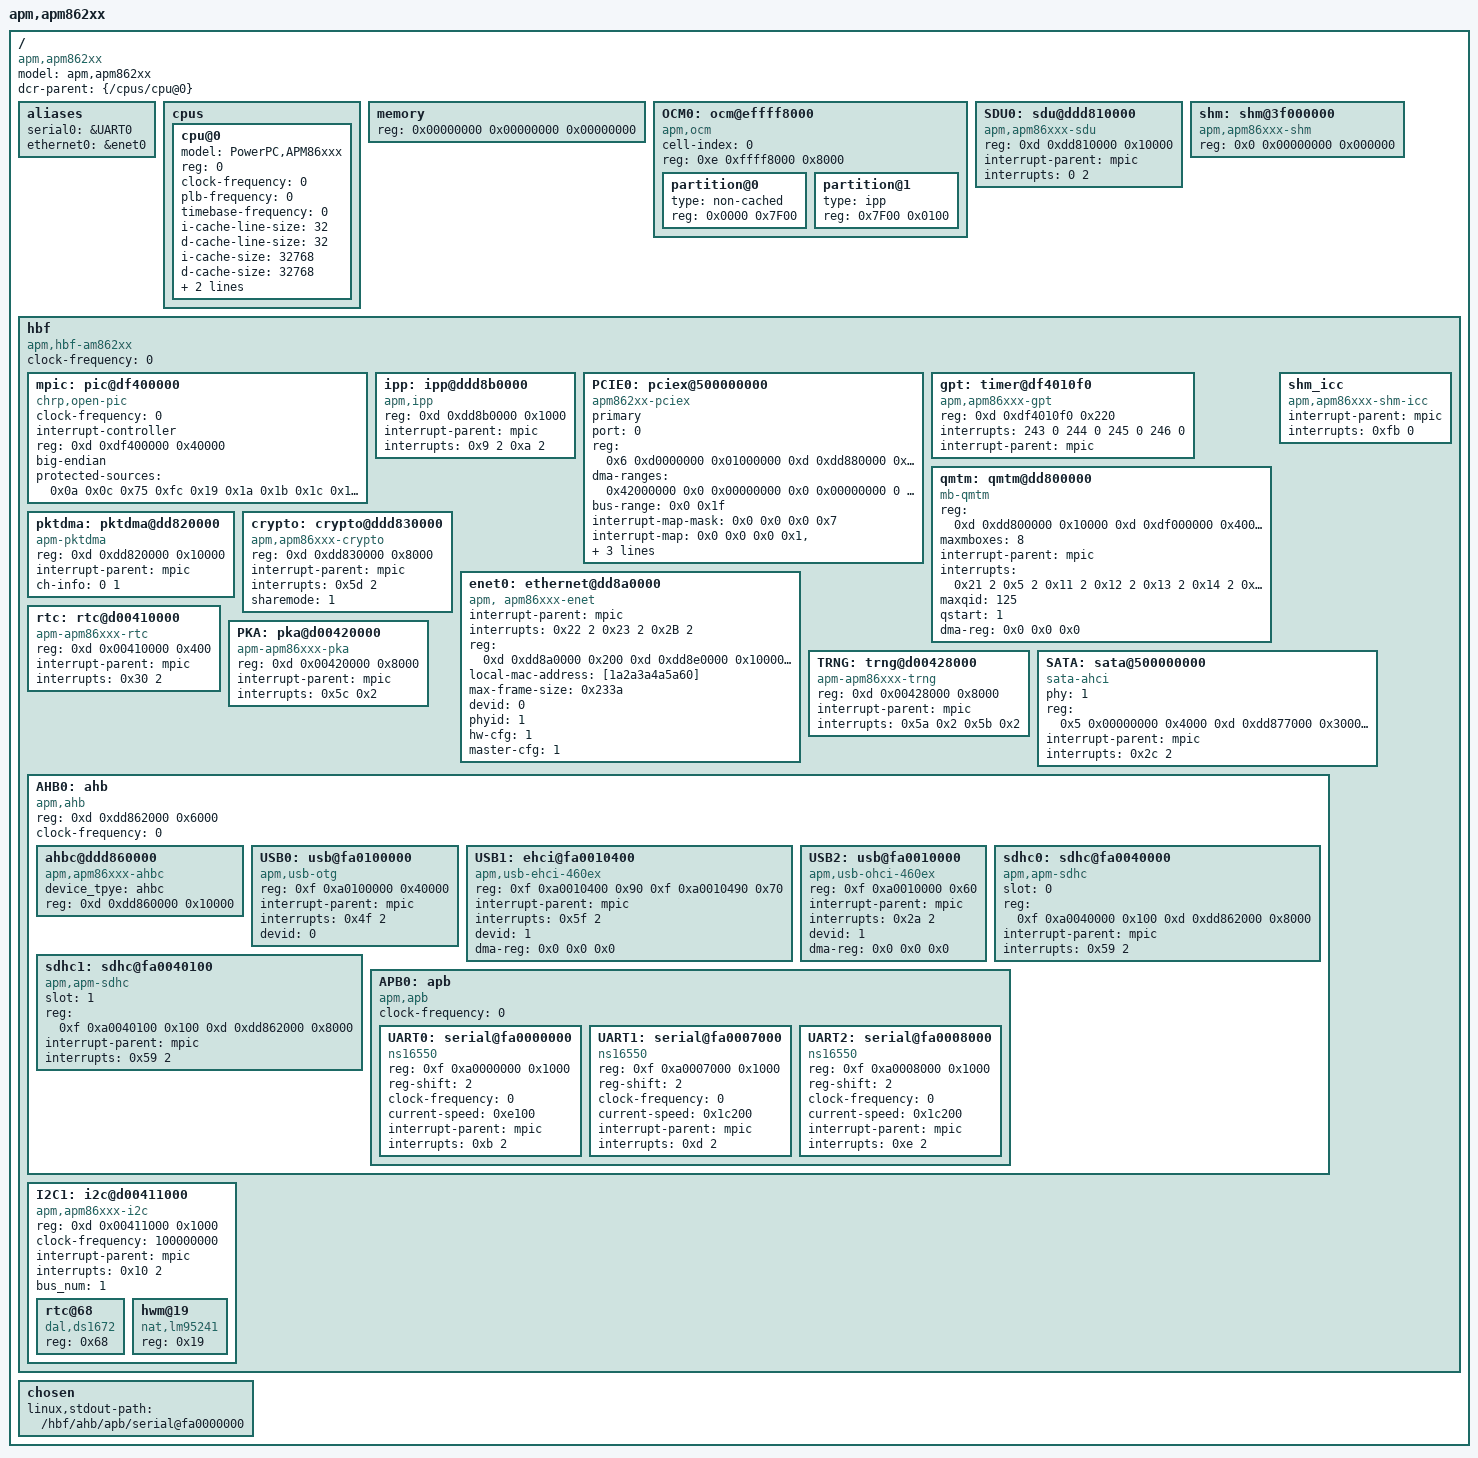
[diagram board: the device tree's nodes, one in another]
/*
 * CPU0 Device Tree Source for APM Serengeti (AM86xxx) Eval Board 
 *
 * Copyright (c) 2010 Applied Micro Circuits Corporation.
 * All rights reserved. Feng Kan <fkan@apm.com>.
 *
 * This file is licensed under the terms of the GNU General Public
 * License version 2.  This program is licensed "as is" without
 * any warranty of any kind, whether express or implied.
 */

/dts-v1/;

/ {
	#address-cells = <2>;
	#size-cells = <1>;
	model = "apm,apm862xx";
	compatible = "apm,apm862xx";
	dcr-parent = <&{/cpus/cpu@0}>;

	aliases {
		serial0 = &UART0;
		ethernet0 = &enet0;
		/*ethernet1 = &enet1;*/
	};

	cpus {
		#address-cells = <1>;
		#size-cells = <0>;

		cpu@0 {
			device_type = "cpu";
			model = "PowerPC,APM86xxx";
			reg = <0>;
			clock-frequency = <0>; /* Filled in by U-Boot */
			plb-frequency = <0>; /* Filled in by U-Boot */
			timebase-frequency = <0>; /* Filled in by U-Boot */
			i-cache-line-size = <32>;
			d-cache-line-size = <32>;
			i-cache-size = <32768>;
			d-cache-size = <32768>;
			dcr-controller;
			dcr-access-method = "native";

			#address-cells = <1>;
			#size-cells = <0>;
		};
	};

	memory {
		device_type = "memory";
		reg = <0x00000000 0x00000000 0x00000000>; /* Filled in by U-Boot */
	};

	OCM0: ocm@effff8000 {
		compatible = "apm,ocm";
		cell-index = <0>;
		reg = <0xe 0xffff8000 0x8000>;
		#size-cells = <1>;
		#address-cells = <1>;
		partition@0 {
			type = "non-cached";
			reg = <0x0000 0x7F00>;
		};
		partition@1 {
			type = "ipp";
			reg = <0x7F00 0x0100>;
		};
	};

	SDU0: sdu@ddd810000 {
		compatible = "apm,apm86xxx-sdu";
		reg = <0xd 0xdd810000 0x10000>;
		interrupt-parent = <&mpic>;
		interrupts = <0 2>;
	};	

	shm: shm@3f000000{
	        compatible = "apm,apm86xxx-shm";
	        reg = <0x0 0x00000000 0x000000>; /* Fill in by U-Boot */
	};

	hbf {
		compatible = "apm,hbf-am862xx", "apm,hbf";
		#address-cells = <2>;
		#size-cells = <1>;
		ranges;
		clock-frequency = <0>; /* Filled in by U-Boot */

                mpic: pic@df400000 {
                        clock-frequency = <0>;
                        interrupt-controller;
                        reg = <0xd 0xdf400000 0x40000>;
			#address-cells = <0>;
                        #interrupt-cells = <2>;
                        compatible = "chrp,open-pic";
                        device_type = "open-pic";
                        big-endian;
			protected-sources = <
                       	0x0a		/* iPP Core1 for other OS */
                       	0x0c		/* UART1 for other OS */
                       	0x75		/* ICC */
			0xfc		/* IPI for other oS */
			0x19 0x1a 0x1b 0x1c 0x1d 0x1e 0x1f 0x20 /* QM mailboxes for core 1*/
			0x26 0x27 0x28 0x29 /* PCIE2 for core 1 */
			0x2e 0x2f	/* USB2 EHCI/OHCI for core 1 */
			0x37 0x38 0x39 0x3a /* PCIE1 for core 1 */
			0xf7 0xf8 0xf9 0xfa /* Timer */
                       	>;
                };

		ipp: ipp@ddd8b0000 {
			compatible = "apm,ipp";
			reg = <0xd 0xdd8b0000 0x1000>;
			interrupt-parent = <&mpic>; 
			interrupts = <  /*iPP Core0 */ 0x9 2  
					/*iPP Core1 */ 0xa 2 >;
		};

		PCIE0: pciex@500000000 {
			device_type = "pci";
			compatible = "apm862xx-pciex", "apm,apm-pciex";
			#interrupt-cells = <1>;
			#size-cells = <2>;
			#address-cells = <3>;
			primary;
			port = <0>;
			status = "ok";
			reg = < 0x6 0xd0000000 0x01000000
				0xd 0xdd880000 0x00008000>;

			ranges = <0x02000000 0x0 0x00000000 0x6 0x00000000 0x0 0x10000000
				  0x02000000 0x0 0x80000000 0x6 0x80000000 0x0 0x10000000
				  0x01000000 0x0 0x10000000 0x6 0x10000000 0x0 0x00010000>;


			dma-ranges = <0x42000000 0x0 0x00000000 0x0 0x00000000 0 0x80000000>;

			bus-range = <0x0 0x1f>;

			interrupt-map-mask = <0x0 0x0 0x0 0x7>;
			interrupt-map = <
				0x0 0x0 0x0 0x1 &mpic 0x33 0x2 
				0x0 0x0 0x0 0x2 &mpic 0x34 0x2 
				0x0 0x0 0x0 0x3 &mpic 0x35 0x2 
				0x0 0x0 0x0 0x4 &mpic 0x36 0x2 >;
		};
/*
		vnet0 {
			device_type = "network";
			compatible = "apm,apm86xxx-vnet";
			local-mac-address = [2a3a4a5a6a60];
			devid = <0>;
			interrupt-parent = <&mpic>;
			interrupts = <0x74 0x2>;
			remote-core-id = <0x01>;
			remote-qm-id = <0x01>;
			remote-msg-idx = <0x01>;
		};
*/
		gpt: timer@df4010f0 {
			compatible = "apm,apm86xxx-gpt";
			reg = <0xd 0xdf4010f0 0x220>;
			interrupts = <243 0 244 0 245 0 246 0>;
			interrupt-parent = <&mpic>;
		};

                qmtm: qmtm@dd800000 {
                        device_type = "qmtm";
                        compatible = "mb-qmtm", "apm,mb-qmtm";
                        #interrupt-cells = <2>;
                        reg =  <0xd 0xdd800000 0x10000   /* QM CSR */
                                0xd 0xdf000000 0x400000  /* QM Fabric */
                                0x3 0xffffd000 0x3fff	/* OCM mailbox */
		 		0xd 0x00000000 0x400000  /* QM lite Fabric */
				0xd 0xdd8d0000 0x10000	/* QM lite CSR */
				0xd 0xdd8b1000 0x240>;	/* iPP QM lite CSR */
			maxmboxes = <8>;
                        interrupt-parent = <&mpic>;
                        interrupts = <  0x21 2  0x5 2 0x11 2 0x12 2 0x13 2 0x14 2 0x15 2 0x16 2 0x17 2 0x18 2>;
			maxqid = <125>;
			qstart = <1>;
			dma-reg = <0x0 0x0 0x0>;			 
                };                
/*
		SLIMPROOFFLOAD { 
			compatible = "apm,slimpro-offload";
			queue = <0 2>;
		}; 
*/
/*
		SRAM0: sram@0x020000000 {
			compatible = "mtd-ram";
			reg = <0x0 0x20000000 0x2000000>; 
			bank-width = <2>;
			#size-cells = <1>;
			#address-cells = <1>;
			partition@0 {
				label = "MTD-RAM Root FS 0";
				reg = <0x00000000 0x01000000>;
			};
			partition@1 {
				label = "MTD-RAM Root FS 1";
				reg = <0x01000000 0x01000000>;
			};
		};
*/
		pktdma: pktdma@dd820000 {
			device_type = "dma";
			compatible = "apm-pktdma", "apm,apm86xxx-pktdma";
			#interrupt-cells = <1>;
			reg = <0xd 0xdd820000 0x10000>;
			interrupt-parent = <&mpic>;
			ch-info = <0 1>;
		};

		crypto: crypto@ddd830000 {
			device_type = "crypto";
			compatible = "apm,apm86xxx-crypto";
			#interrupt-cells = <1>;
			reg = <0xd 0xdd830000 0x8000>; 
			interrupt-parent = <&mpic>;
			interrupts = <0x5d 2>;
			sharemode = <1>; 
		};

		shm_icc {
			compatible = "apm,apm86xxx-shm-icc";
			interrupt-parent = <&mpic>;
			interrupts = <0xfb 0>;
		};

		enet0: ethernet@dd8a0000 {
			device_type = "network";
			compatible = "apm, apm86xxx-enet";
			interrupt-parent = <&mpic>;
			interrupts = <0x22 2     /* Enet Int */ 
                                      0x23 2     /* Enet MAC Int */ 
                                      0x2B 2 >;  /* Enet QMI Int */
			reg = <0xd 0xdd8a0000 0x200     /* enet port CSR */
			       0xd 0xdd8e0000 0x10000   /* classifier CSR */
			       0xd 0xdd8a0800 0xF800    /* enet gbl CSR */
			       0xd 0xdd8a0000 0x20>;    /* enet mii access CSR */
			local-mac-address = [1a2a3a4a5a60]; 
			max-frame-size = <0x233a>;
			devid = <0>;
			phyid = <1>;
			hw-cfg = <1>;
			master-cfg = <1>;
                };
/*
	        enet1: ethernet@dd8a0030 {
			device_type = "network";
			compatible = "apm, apm86xxx-enet";
			interrupt-parent = <&mpic>;
			interrupts = <0x22 2      
                                      0x23 2      
                                      0x2B 2 >;  
			reg = <0xd 0xdd8a0030 0x200     
			       0xd 0xdd8e0000 0x10000   
			       0xd 0xdd8a0800 0xF800
			       0xd 0xdd8a0000 0x20>;
			local-mac-address = [1a2a3a4a5a61]; 
			max-frame-size = <0x233a>;
			devid = <1>;
			phyid = <2>;
                };

		lac: lac@ddd8e0000 {
			device_type = "classifier";
			compatible = "apm,apm86xxx-lac";
			reg = < 0xd 0xdd8e0000 0x10000>;
			sharemode = <1>;
		};
*/

		rtc:	rtc@d00410000 {
			device_type = "rtc";
			compatible = "apm-apm86xxx-rtc";
			reg = <0xd 0x00410000 0x400>;
			interrupt-parent = <&mpic>;
			interrupts = <0x30 2>;
		};

		PKA: pka@d00420000 {
			device_type = "pka";
			compatible = "apm-apm86xxx-pka";
			reg = <0xd 0x00420000 0x8000>;
			interrupt-parent = <&mpic>;
			interrupts = <0x5c 0x2>;
		};

		TRNG: trng@d00428000 {
			device_type = "trng";
			compatible = "apm-apm86xxx-trng";
			reg = <0xd 0x00428000 0x8000>;
			interrupt-parent = <&mpic>;
			interrupts = <0x5a 0x2 0x5b 0x2>;
		};

		SATA:	sata@500000000 {
			device_type = "sata";
			compatible = "sata-ahci", "apm,sata-ahci";
			phy = <1>;
			reg = <0x5 0x00000000 0x4000
                               0xd 0xdd877000 0x3000
                               0xd 0xdd870000 0x7000
                               0xd 0xdd880000 0x10000>;
			interrupt-parent = <&mpic>;
			interrupts = <0x2c 2>;
		};
/*
		lcd: lcd@ddf440000 {
			device_type = "lcd";
			compatible = "apm,apm-lcd";
			reg = <0xd 0xdf440000 0x2000
			       0xd 0xdd817000 0x100>;
			interrupt-parent = <&mpic>;
			interrupts = <0x01 2>;
			overlay = <3>;
			frame = <2>;
		};
*/
		AHB0: ahb {
			device_type = "ahb";
			compatible = "apm,ahb";
			#address-cells = <2>;
			#size-cells = <1>;
			reg = <0xd 0xdd862000 0x6000>;
			ranges;
			clock-frequency = <0>; /* Filled in by U-Boot */

	                ahbc@ddd860000 {
	                        device_tpye = "ahbc";
                        	compatible = "apm,apm86xxx-ahbc";
				reg = <0xd 0xdd860000 0x10000>;
		        };

			USB0: usb@fa0100000 {
				device_type = "usb";
				compatible = "apm,usb-otg";
				reg = <0xf 0xa0100000 0x40000>;
				interrupt-parent = <&mpic>;
				interrupts = <0x4f 2>;
				devid = <0>;
			};

			USB1: ehci@fa0010400 {
				compatible = "apm,usb-ehci-460ex", "usb-ehci";
				reg = <0xf 0xa0010400 0x90 0xf 0xa0010490 0x70>;
				interrupt-parent = <&mpic>;
				interrupts = <0x5f 2>;
				devid = <1>;
				dma-reg = <0x0 0x0 0x0>;			 
			};

			USB2: usb@fa0010000 {
				compatible = "apm,usb-ohci-460ex", "usb-ohci","ohci-le";
				reg = <0xf 0xa0010000 0x60>;
				interrupt-parent = <&mpic>;
				interrupts = <0x2a 2>;
				devid = <1>;
				dma-reg = <0x0 0x0 0x0>;			 
			};

			sdhc0: sdhc@fa0040000 {
				device_type = "sdhc";
				compatible = "apm,apm-sdhc";
				#interrupt-cells = <1>;
				slot = <0>;
				reg = <0xf 0xa0040000 0x100
					0xd 0xdd862000 0x8000>;
				interrupt-parent = <&mpic>;
				interrupts = <0x59 2>;
			};

			sdhc1: sdhc@fa0040100 {
				device_type = "sdhc";
				compatible = "apm,apm-sdhc";
				#interrupt-cells = <1>;
				slot = <1>;
				reg = <0xf 0xa0040100 0x100
					0xd 0xdd862000 0x8000>;
				interrupt-parent = <&mpic>;
				interrupts = <0x59 2>;
			};

			APB0: apb {
				compatible = "apm,apb";
				device_type = "apb";
				#address-cells = <2>;
				#size-cells = <1>;
				ranges;
				clock-frequency = <0>; /* Filled in by U-Boot */

				UART0: serial@fa0000000 {
					device_type = "serial";
					compatible = "ns16550";
					reg = <0xf 0xa0000000 0x1000>;
					reg-shift = <2>;
					clock-frequency = <0>; /* Filled in by U-Boot */
					current-speed = <0xe100>;
					interrupt-parent = <&mpic>;
					interrupts = <0xb 2>;
				};

				UART1: serial@fa0007000 {
					device_type = "serial";
					compatible = "ns16550";
					reg = <0xf 0xa0007000 0x1000>;
					reg-shift = <2>;
					clock-frequency = <0>; 
					current-speed = <0x1c200>;
					interrupt-parent = <&mpic>;
					interrupts = <0xd 2>;
				};

				UART2: serial@fa0008000 {
					device_type = "serial";
					compatible = "ns16550";
					reg = <0xf 0xa0008000 0x1000>;
					reg-shift = <2>;
					clock-frequency = <0>; 
					current-speed = <0x1c200>;
					interrupt-parent = <&mpic>;
					interrupts = <0xe 2>;
				};

/*
				SPI0:	spi@fa0005000 {
				 	device_type = "spi";
					compatible = "apm,spi";
					#address-cells = <1>;
					#size-cells = <0>;
					reg = <0xf 0xa0005000 0x1000>;
					interrupt-parent = <&mpic>;
					interrupts = <0x52 2>;
					sysclk = <62000000>;
					bus_num = <0x0>;

					SFLASH: m25p80@0 {
						compatible = "stm,m25p80","jedec-flash";
						reg = <0>;
						spi-max-frequency = <3100000>;
						spi-cpha;
						spi-cpol;
					};
				};

				GPIO:	gpio@fa0004000 {
					device_type = "gpio";
					compatible = "apm,apm86xxx-gpio";
					reg = <0xf 0xa0004000 0x1000>;
					gpio-count = <0x1a>;
				};
*/
			};
		};

		I2C1:	i2c@d00411000 {
			device_type = "i2c";
			compatible = "apm,apm86xxx-i2c";
			reg = <0xd 0x00411000 0x1000>;
			clock-frequency = <100000000>;
			interrupt-parent = <&mpic>;
			interrupts = <0x10 2>;
			bus_num = <1>;
			#address-cells = <1>;
			#size-cells = <0>;
			rtc@68 {
                        	compatible = "dal,ds1672";
                        	reg = <0x68>;
			};
			
			hwm@19 {
                        	compatible = "nat,lm95241";
                        	reg = <0x19>;
			};
		};
	};
	chosen {
		linux,stdout-path = "/hbf/ahb/apb/serial@fa0000000";
	};

};
